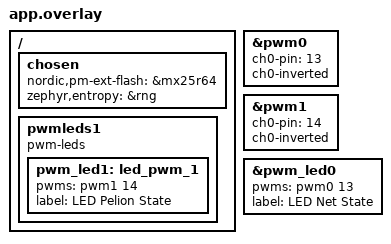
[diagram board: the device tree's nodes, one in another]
/* Copyright (c) 2021 Nordic Semiconductor ASA
 *
 * SPDX-License-Identifier: LicenseRef-Nordic-5-Clause
 */

/ {
	chosen {
		nordic,pm-ext-flash = &mx25r64;
	};
};

/ {
	/*
	* In some default configurations within the nRF Connect SDK,
	* e.g. on nRF52840, the chosen zephyr,entropy node is &cryptocell.
	* This devicetree overlay ensures that default is overridden wherever it
	* is set, as this application uses the RNG node for entropy exclusively.
	*/
	chosen {
		zephyr,entropy = &rng;
	};

	pwmleds1 {
		compatible = "pwm-leds";
		status = "okay";

		pwm_led1: led_pwm_1 {
			status = "okay";
			pwms = <&pwm1 14>;
			label = "LED Pelion State";
		};
	};
};

&pwm0 {
	status = "okay";
	ch0-pin = <13>;
	ch0-inverted;
};

&pwm1 {
	status = "okay";
	ch0-pin = <14>;
	ch0-inverted;
};

&pwm_led0 {
	status = "okay";
	pwms = <&pwm0 13>;
	label = "LED Net State";
};
